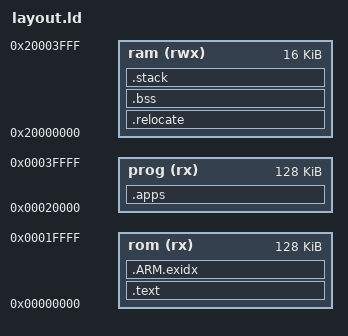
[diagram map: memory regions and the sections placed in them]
/*
 * This is an example linker script. Copy this into your Tock board repository
 * and modify as needed.
 */

OUTPUT_FORMAT("elf32-littlearm", "elf32-littlearm", "elf32-littlearm")
OUTPUT_ARCH(arm)
SEARCH_DIR(.)

MEMORY
{
  rom (rx)  : ORIGIN = 0x00000000, LENGTH = 128K
  prog (rx) : ORIGIN = 0x00020000, LENGTH = 128K
  ram (rwx) : ORIGIN = 0x20000000, LENGTH = 16K
}

__stack_size__ = DEFINED(__stack_size__) ? __stack_size__ : 0x1000;
__ram_end__ = ORIGIN(ram) + LENGTH(ram) - 4;

/* Section Definitions */
SECTIONS
{
    .text :
    {
        . = ALIGN(4);
        _sfixed = .;
        _textstart = .;
        KEEP(*(.vectors .vectors.*))
        *(.text .text.* .gnu.linkonce.t.*)
        *(.glue_7t) *(.glue_7)
        *(.rodata .rodata* .gnu.linkonce.r.*)
        *(.ARM.extab* .gnu.linkonce.armextab.*)

        KEEP (*(.syscalls))


        . = ALIGN(4);
        KEEP(*(.init))
        . = ALIGN(4);
        __preinit_array_start = .;
        KEEP (*(.preinit_array))
        __preinit_array_end = .;

        . = ALIGN(4);
        __init_array_start = .;
        KEEP (*(SORT(.init_array.*)))
        KEEP (*(.init_array))
        __init_array_end = .;

        . = ALIGN(4);
        KEEP (*crtbegin.o(.ctors))
        KEEP (*(EXCLUDE_FILE (*crtend.o) .ctors))
        KEEP (*(SORT(.ctors.*)))
        KEEP (*crtend.o(.ctors))

        . = ALIGN(4);
        KEEP(*(.fini))

        . = ALIGN(4);
        __fini_array_start = .;
        KEEP (*(.fini_array))
        KEEP (*(SORT(.fini_array.*)))
        __fini_array_end = .;

        KEEP (*crtbegin.o(.dtors))
        KEEP (*(EXCLUDE_FILE (*crtend.o) .dtors))
        KEEP (*(SORT(.dtors.*)))
        KEEP (*crtend.o(.dtors))

        *(.got*)

        . = ALIGN(4);
        _efixed = .;            /* End of text section */
    } > rom

    .apps :
    {
        . = ALIGN(4);
        _sapps = .;
        KEEP (*(.app.*))
	LONG(0)
        _eapps = .;
    } > prog

    /* .ARM.exidx is sorted, so has to go in its own output section.  */
    PROVIDE_HIDDEN (__exidx_start = .);
    .ARM.exidx :
    {
      *(.ARM.exidx* .gnu.linkonce.armexidx.*)
    } > rom
    PROVIDE_HIDDEN (__exidx_end = .);

    . = ALIGN(4);
    _etext = .;
    _textend = .;

    .relocate : AT (_etext)
    {
        . = ALIGN(4);
        _srelocate = .;
        *(.ramfunc .ramfunc.*);
        *(.data .data.*);

        . = ALIGN(4);
        _erelocate = .;
    } > ram

    /* .bss section which is used for uninitialized data */
    .bss (NOLOAD) :
    {
        . = ALIGN(4);
        _sbss = . ;
        _szero = .;
        *(.bss .bss.*)
        *(COMMON)
        . = ALIGN(4);
        _ebss = . ;

        . = ALIGN(8);
        *(.app_memory)

        _ezero = .;
    } > ram

    /* stack section */
    .stack (NOLOAD):
    {
        . = ALIGN(8);
         _sstack = .;
        . = . + __stack_size__;
        . = ALIGN(8);
        _estack = .;
    } > ram

    . = ALIGN(4);
    _end = . ;
}
